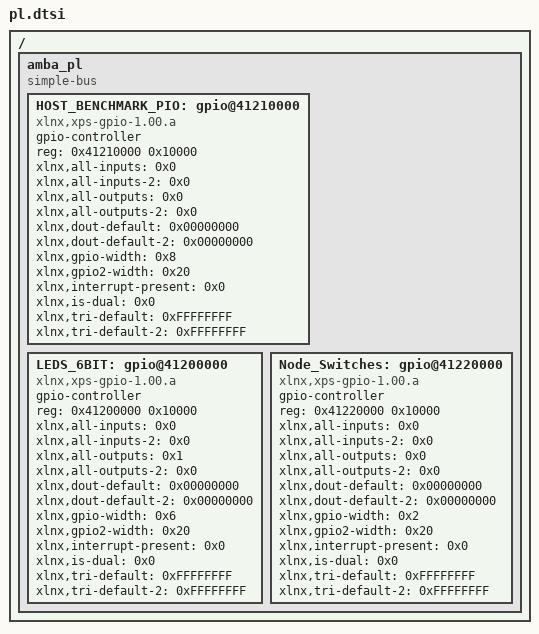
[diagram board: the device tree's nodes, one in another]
/*
 * CAUTION: This file is automatically generated by Xilinx.
 * Version:
 * Today is: Wed Jul 27 13:22:49 2016
*/


/ {
    amba_pl: amba_pl {
        #address-cells = <1>;
        #size-cells = <1>;
        compatible = "simple-bus";
        ranges ;
        HOST_BENCHMARK_PIO: gpio@41210000 {
            #gpio-cells = <2>;
            compatible = "xlnx,xps-gpio-1.00.a";
            gpio-controller ;
            reg = <0x41210000 0x10000>;
            xlnx,all-inputs = <0x0>;
            xlnx,all-inputs-2 = <0x0>;
            xlnx,all-outputs = <0x0>;
            xlnx,all-outputs-2 = <0x0>;
            xlnx,dout-default = <0x00000000>;
            xlnx,dout-default-2 = <0x00000000>;
            xlnx,gpio-width = <0x8>;
            xlnx,gpio2-width = <0x20>;
            xlnx,interrupt-present = <0x0>;
            xlnx,is-dual = <0x0>;
            xlnx,tri-default = <0xFFFFFFFF>;
            xlnx,tri-default-2 = <0xFFFFFFFF>;
        };
        LEDS_6BIT: gpio@41200000 {
            #gpio-cells = <2>;
            compatible = "xlnx,xps-gpio-1.00.a";
            gpio-controller ;
            reg = <0x41200000 0x10000>;
            xlnx,all-inputs = <0x0>;
            xlnx,all-inputs-2 = <0x0>;
            xlnx,all-outputs = <0x1>;
            xlnx,all-outputs-2 = <0x0>;
            xlnx,dout-default = <0x00000000>;
            xlnx,dout-default-2 = <0x00000000>;
            xlnx,gpio-width = <0x6>;
            xlnx,gpio2-width = <0x20>;
            xlnx,interrupt-present = <0x0>;
            xlnx,is-dual = <0x0>;
            xlnx,tri-default = <0xFFFFFFFF>;
            xlnx,tri-default-2 = <0xFFFFFFFF>;
        };
        Node_Switches: gpio@41220000 {
            #gpio-cells = <2>;
            compatible = "xlnx,xps-gpio-1.00.a";
            gpio-controller ;
            reg = <0x41220000 0x10000>;
            xlnx,all-inputs = <0x0>;
            xlnx,all-inputs-2 = <0x0>;
            xlnx,all-outputs = <0x0>;
            xlnx,all-outputs-2 = <0x0>;
            xlnx,dout-default = <0x00000000>;
            xlnx,dout-default-2 = <0x00000000>;
            xlnx,gpio-width = <0x2>;
            xlnx,gpio2-width = <0x20>;
            xlnx,interrupt-present = <0x0>;
            xlnx,is-dual = <0x0>;
            xlnx,tri-default = <0xFFFFFFFF>;
            xlnx,tri-default-2 = <0xFFFFFFFF>;
        };
    };
};
